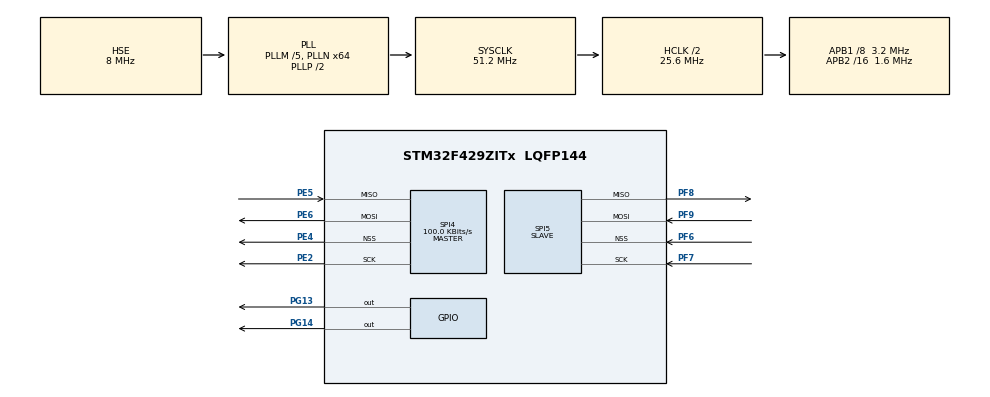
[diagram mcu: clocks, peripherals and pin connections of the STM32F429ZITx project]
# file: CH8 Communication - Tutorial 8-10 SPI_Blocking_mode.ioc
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Mcu.Family=STM32F4
Mcu.Name=STM32F429ZITx
Mcu.Package=LQFP144
NVIC.PriorityGroup=NVIC_PRIORITYGROUP_0
PE2.Mode=Full_Duplex_Master
PE2.Signal=SPI4_SCK
PE4.Mode=NSS_Signal_Hard_Output
PE4.Signal=SPI4_NSS
PE5.Mode=Full_Duplex_Master
PE5.Signal=SPI4_MISO
PE6.Mode=Full_Duplex_Master
PE6.Signal=SPI4_MOSI
PF6.Mode=NSS_Signal_Hard_Input
PF6.Signal=SPI5_NSS
PF7.Mode=Full_Duplex_Slave
PF7.Signal=SPI5_SCK
PF8.Mode=Full_Duplex_Slave
PF8.Signal=SPI5_MISO
PF9.Mode=Full_Duplex_Slave
PF9.Signal=SPI5_MOSI
PG13.Signal=GPIO_Output
PG14.Signal=GPIO_Output
PH0/OSC_IN.Mode=HSE-External-Oscillator
PH0/OSC_IN.Signal=RCC_OSC_IN
PH1/OSC_OUT.Mode=HSE-External-Oscillator
PH1/OSC_OUT.Signal=RCC_OSC_OUT
ProjectManager.HeapSize=0x200
ProjectManager.StackSize=0x400
ProjectManager.TargetToolchain=STM32CubeIDE
RCC.48MHZClocksFreq_Value=14628571.42857143
RCC.AHBCLKDivider=RCC_SYSCLK_DIV2
RCC.AHBFreq_Value=25600000
RCC.APB1CLKDivider=RCC_HCLK_DIV8
RCC.APB1Freq_Value=3200000
RCC.APB1TimFreq_Value=6400000
RCC.APB2CLKDivider=RCC_HCLK_DIV16
RCC.APB2Freq_Value=1600000
RCC.APB2TimFreq_Value=3200000
RCC.CortexFreq_Value=25600000
RCC.HCLKFreq_Value=25600000
RCC.HSE_VALUE=8000000
RCC.HSI_VALUE=16000000
RCC.LSE_VALUE=32768
RCC.PLLM=5
RCC.PLLN=64
RCC.PLLQ=7
RCC.PLLSourceVirtual=RCC_PLLSOURCE_HSE
RCC.SYSCLKFreq_VALUE=51200000
RCC.SYSCLKSource=RCC_SYSCLKSOURCE_PLLCLK
RCC.VCOOutputFreq_Value=102400000
SPI4.BaudRatePrescaler=SPI_BAUDRATEPRESCALER_16
SPI4.CalculateBaudRate=100.0 KBits/s
SPI4.Direction=SPI_DIRECTION_2LINES
SPI4.Mode=SPI_MODE_MASTER
SPI4.VirtualNSS=VM_NSSHARD
SPI4.VirtualType=VM_MASTER
SPI5.Direction=SPI_DIRECTION_2LINES
SPI5.Mode=SPI_MODE_SLAVE
SPI5.VirtualNSS=VM_NSSHARD
SPI5.VirtualType=VM_SLAVE
board=STM32F429I-DISC1

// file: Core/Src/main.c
/* USER CODE BEGIN Header */
/**
  ******************************************************************************
  * @file           : main.c
  * @brief          : Main program body
  ******************************************************************************
  * @attention
  *
  * Copyright (c) 2024 STMicroelectronics.
  * All rights reserved.
  *
  * This software is licensed under terms that can be found in the LICENSE file
  * in the root directory of this software component.
  * If no LICENSE file comes with this software, it is provided AS-IS.
  *
  ******************************************************************************
  */

	/***************************** Tutorial Tags ******************************
		 SPI Full duplex
		 GPIO Digital outputs
	 **************************************************************************/

	/* 8.3.4 SPI Usage in the STM32F4Microcontroller: *************************
	 * Tutorial 8-10: Usage of the SPI module in blocking operation mode, the C code

	Make a project to send data from SPI4 to SPI5 set as master and slave respectively.
	There are two counter values in the
	code. The first one will be sent to the slave from master. Upon receiving this data
	by the slave, the green LED connected to pin PG13 of the STM32F4 board will
	toggle if mod 3 of the received counter value is equal to zero. Afterward, the second
	counter will be sent to master from slave. Upon receiving this data by the master,
	the red LED connected to pin PG14 of the STM32F4 board will toggle if mod 5 of
	the received counter value is equal to zero. This operation will repeat every 2 s.
	***************************************************************************/

/* USER CODE END Header */
#include "main.h"

SPI_HandleTypeDef hspi4;
SPI_HandleTypeDef hspi5;

/* USER CODE BEGIN PV */
// Data to be sent by master and slave
uint8_t masterTxdata = 0, slaveTxdata = 0;

// Buffer for receive data by master and slave
uint8_t masterRxdata, slaveRxdata;

/* USER CODE END PV */

void SystemClock_Config(void);
static void MX_GPIO_Init(void);
static void MX_SPI4_Init(void);
static void MX_SPI5_Init(void);

int main(void)
{

  /* MCU Configuration--------------------------------------------------------*/

  /* Reset of all peripherals, Initializes the Flash interface and the Systick. */
  HAL_Init();

  /* Configure the system clock */
  SystemClock_Config();

  /* Initialize all configured peripherals */
  MX_GPIO_Init();
  MX_SPI4_Init();
  MX_SPI5_Init();

  /* Infinite loop */
  /* USER CODE BEGIN WHILE */

  while (1)
  {
	  masterTxdata++;
	  slaveTxdata++;

	  // Transmit data between Master SPI4 to Slave SPI5 in duplex mode

	  HAL_SPI_TransmitReceive(&hspi4, &masterTxdata, &masterRxdata, 1, 1000);

	  HAL_SPI_TransmitReceive(&hspi5, &slaveTxdata, &slaveRxdata, 1, 1000);

	  if(masterRxdata %5 ==0)
	 		  HAL_GPIO_TogglePin(GPIOG, GPIO_PIN_14);

	  if(slaveRxdata %3 ==0)
		  HAL_GPIO_TogglePin(GPIOG, GPIO_PIN_13);

	  // Delay 2 seconds
	  HAL_Delay(2000);

    /* USER CODE END WHILE */

  }
}

void SystemClock_Config(void)
{
  RCC_OscInitTypeDef RCC_OscInitStruct = {0};
  RCC_ClkInitTypeDef RCC_ClkInitStruct = {0};

  /** Configure the main internal regulator output voltage
  */
  __HAL_RCC_PWR_CLK_ENABLE();
  __HAL_PWR_VOLTAGESCALING_CONFIG(PWR_REGULATOR_VOLTAGE_SCALE3);

  /** Initializes the RCC Oscillators according to the specified parameters
  * in the RCC_OscInitTypeDef structure.
  */
  RCC_OscInitStruct.OscillatorType = RCC_OSCILLATORTYPE_HSE;
  RCC_OscInitStruct.HSEState = RCC_HSE_ON;
  RCC_OscInitStruct.PLL.PLLState = RCC_PLL_ON;
  RCC_OscInitStruct.PLL.PLLSource = RCC_PLLSOURCE_HSE;
  RCC_OscInitStruct.PLL.PLLM = 5;
  RCC_OscInitStruct.PLL.PLLN = 64;
  RCC_OscInitStruct.PLL.PLLP = RCC_PLLP_DIV2;
  RCC_OscInitStruct.PLL.PLLQ = 7;
  if (HAL_RCC_OscConfig(&RCC_OscInitStruct) != HAL_OK)
  {
    Error_Handler();
  }

  /** Initializes the CPU, AHB and APB buses clocks
  */
  RCC_ClkInitStruct.ClockType = RCC_CLOCKTYPE_HCLK|RCC_CLOCKTYPE_SYSCLK
                              |RCC_CLOCKTYPE_PCLK1|RCC_CLOCKTYPE_PCLK2;
  RCC_ClkInitStruct.SYSCLKSource = RCC_SYSCLKSOURCE_PLLCLK;
  RCC_ClkInitStruct.AHBCLKDivider = RCC_SYSCLK_DIV2;
  RCC_ClkInitStruct.APB1CLKDivider = RCC_HCLK_DIV8;
  RCC_ClkInitStruct.APB2CLKDivider = RCC_HCLK_DIV16;

  if (HAL_RCC_ClockConfig(&RCC_ClkInitStruct, FLASH_LATENCY_0) != HAL_OK)
  {
    Error_Handler();
  }
}

static void MX_SPI4_Init(void)
{

  /* SPI4 parameter configuration*/
  hspi4.Instance = SPI4;
  hspi4.Init.Mode = SPI_MODE_MASTER;
  hspi4.Init.Direction = SPI_DIRECTION_2LINES;
  hspi4.Init.DataSize = SPI_DATASIZE_8BIT;
  hspi4.Init.CLKPolarity = SPI_POLARITY_LOW;
  hspi4.Init.CLKPhase = SPI_PHASE_1EDGE;
  hspi4.Init.NSS = SPI_NSS_HARD_OUTPUT;
  hspi4.Init.BaudRatePrescaler = SPI_BAUDRATEPRESCALER_16;
  hspi4.Init.FirstBit = SPI_FIRSTBIT_MSB;
  hspi4.Init.TIMode = SPI_TIMODE_DISABLE;
  hspi4.Init.CRCCalculation = SPI_CRCCALCULATION_DISABLE;
  hspi4.Init.CRCPolynomial = 10;
  if (HAL_SPI_Init(&hspi4) != HAL_OK)
  {
    Error_Handler();
  }

}

static void MX_SPI5_Init(void)
{

  /* SPI5 parameter configuration*/
  hspi5.Instance = SPI5;
  hspi5.Init.Mode = SPI_MODE_SLAVE;
  hspi5.Init.Direction = SPI_DIRECTION_2LINES;
  hspi5.Init.DataSize = SPI_DATASIZE_8BIT;
  hspi5.Init.CLKPolarity = SPI_POLARITY_LOW;
  hspi5.Init.CLKPhase = SPI_PHASE_1EDGE;
  hspi5.Init.NSS = SPI_NSS_HARD_INPUT;
  hspi5.Init.FirstBit = SPI_FIRSTBIT_MSB;
  hspi5.Init.TIMode = SPI_TIMODE_DISABLE;
  hspi5.Init.CRCCalculation = SPI_CRCCALCULATION_DISABLE;
  hspi5.Init.CRCPolynomial = 10;
  if (HAL_SPI_Init(&hspi5) != HAL_OK)
  {
    Error_Handler();
  }

}

static void MX_GPIO_Init(void)
{
  GPIO_InitTypeDef GPIO_InitStruct = {0};

  /* GPIO Ports Clock Enable */
  __HAL_RCC_GPIOE_CLK_ENABLE();
  __HAL_RCC_GPIOF_CLK_ENABLE();
  __HAL_RCC_GPIOH_CLK_ENABLE();
  __HAL_RCC_GPIOG_CLK_ENABLE();

  /*Configure GPIO pin Output Level */
  HAL_GPIO_WritePin(GPIOG, GPIO_PIN_13|GPIO_PIN_14, GPIO_PIN_RESET);

  /*Configure GPIO pins : PG13 PG14 */
  GPIO_InitStruct.Pin = GPIO_PIN_13|GPIO_PIN_14;
  GPIO_InitStruct.Mode = GPIO_MODE_OUTPUT_PP;
  GPIO_InitStruct.Pull = GPIO_NOPULL;
  GPIO_InitStruct.Speed = GPIO_SPEED_FREQ_LOW;
  HAL_GPIO_Init(GPIOG, &GPIO_InitStruct);

}

void Error_Handler(void)
{
  __disable_irq();
  while (1)
  {
  }
}
